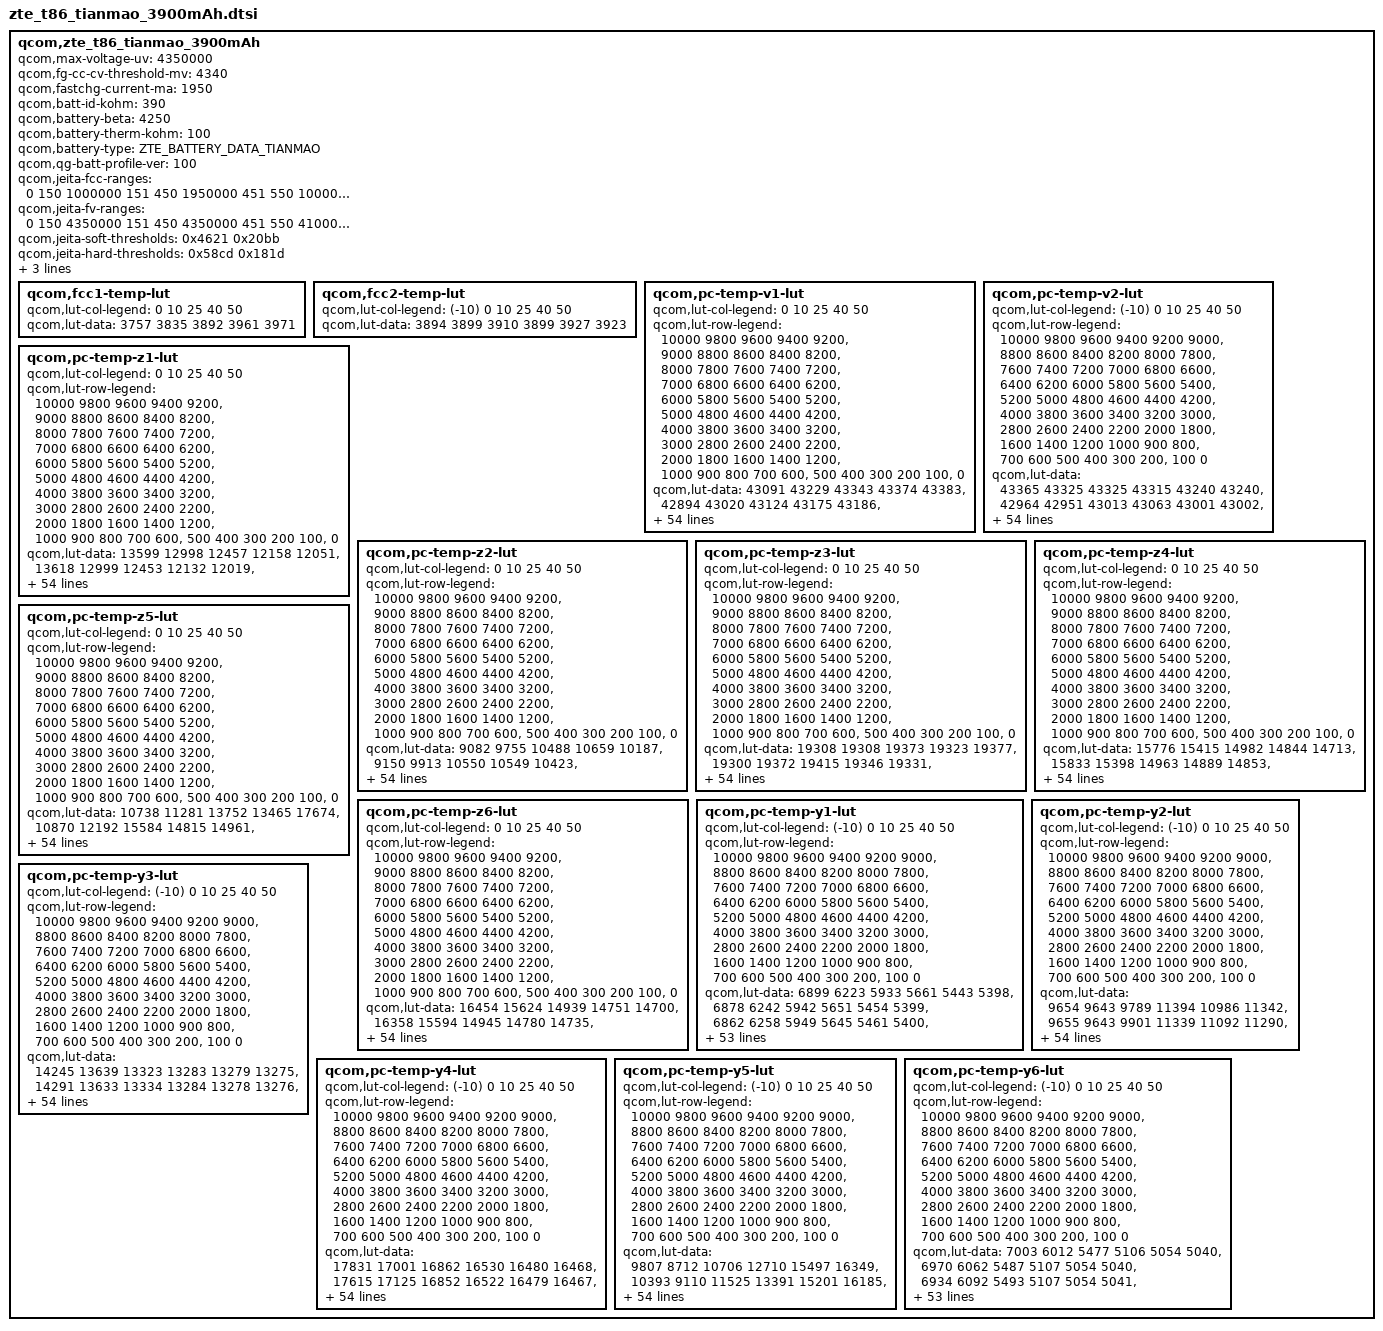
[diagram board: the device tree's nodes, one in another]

qcom,zte_t86_tianmao_3900mAh {
	/* 4215010_ZTE_T86_3900mAH_PMI632_averaged_MasterSlave_Sep26th2019 */
	qcom,max-voltage-uv = <4350000>;
	qcom,fg-cc-cv-threshold-mv = <4340>;
	qcom,fastchg-current-ma = <1950>;
	qcom,batt-id-kohm = <390>;
	qcom,battery-beta = <4250>;
	qcom,battery-therm-kohm = <100>;
	qcom,battery-type = "ZTE_BATTERY_DATA_TIANMAO";
	qcom,qg-batt-profile-ver = <100>;

	qcom,jeita-fcc-ranges = <0   150   1000000
				 151 450  1950000
				 451 550  1000000>;
	qcom,jeita-fv-ranges =  <0   150  4350000
				 151 450  4350000
				 451 550  4100000>;

	/* COOL = 15 DegC, WARM = 45 DegC */
	qcom,jeita-soft-thresholds = <0x4621 0x20bb>;
	/* COLD = 0 DegC, HOT = 55 DegC */
	qcom,jeita-hard-thresholds = <0x58cd 0x181d>;
	/* COOL hys = 17 DegC, WARM hys = 43 DegC */
	qcom,jeita-soft-hys-thresholds = <0x4365 0x22b8>;
	qcom,jeita-soft-fcc-ua = <1000000 1000000>;
	qcom,jeita-soft-fv-uv = <4350000 4100000>;

	qcom,fcc1-temp-lut {
		qcom,lut-col-legend = <0 10 25 40 50>;
		qcom,lut-data = <3757 3835 3892 3961 3971>;
	};

	qcom,fcc2-temp-lut {
		qcom,lut-col-legend = <(-10) 0 10 25 40 50>;
		qcom,lut-data = <3894 3899 3910 3899 3927 3923>;
	};

	qcom,pc-temp-v1-lut {
		qcom,lut-col-legend = <0 10 25 40 50>;
		qcom,lut-row-legend = <10000 9800 9600 9400 9200>,
			<9000 8800 8600 8400 8200>,
			<8000 7800 7600 7400 7200>,
			<7000 6800 6600 6400 6200>,
			<6000 5800 5600 5400 5200>,
			<5000 4800 4600 4400 4200>,
			<4000 3800 3600 3400 3200>,
			<3000 2800 2600 2400 2200>,
			<2000 1800 1600 1400 1200>,
			<1000 900 800 700 600>,
			<500 400 300 200 100>,
			<0>;
		qcom,lut-data = <43091 43229 43343 43374 43383>,
			<42894 43020 43124 43175 43186>,
			<42683 42806 42905 42956 42973>,
			<42470 42583 42687 42730 42750>,
			<42268 42363 42468 42510 42532>,
			<42072 42156 42253 42293 42314>,
			<41882 41957 42043 42076 42097>,
			<41693 41762 41836 41860 41882>,
			<41508 41568 41631 41647 41670>,
			<41337 41380 41426 41435 41458>,
			<41183 41216 41235 41227 41249>,
			<41007 41073 41078 41036 41045>,
			<40743 40895 40923 40870 40848>,
			<40423 40601 40707 40695 40656>,
			<40175 40282 40409 40472 40468>,
			<39993 40078 40162 40231 40283>,
			<39840 39935 40017 40049 40110>,
			<39711 39804 39895 39919 39952>,
			<39602 39681 39739 39781 39789>,
			<39488 39558 39550 39592 39599>,
			<39362 39384 39360 39381 39396>,
			<39225 39128 39167 39188 39204>,
			<39068 38920 38984 39004 39015>,
			<38874 38818 38846 38848 38853>,
			<38717 38744 38739 38728 38727>,
			<38628 38671 38642 38624 38619>,
			<38563 38600 38548 38525 38519>,
			<38507 38534 38461 38433 38428>,
			<38460 38471 38380 38349 38342>,
			<38418 38412 38306 38274 38262>,
			<38379 38359 38239 38206 38189>,
			<38343 38311 38180 38144 38123>,
			<38307 38268 38128 38088 38066>,
			<38274 38228 38080 38035 38007>,
			<38241 38193 38038 37986 37949>,
			<38206 38154 37995 37937 37889>,
			<38169 38117 37951 37884 37824>,
			<38124 38073 37904 37827 37757>,
			<38052 38002 37837 37755 37679>,
			<37954 37896 37742 37660 37587>,
			<37851 37778 37634 37550 37482>,
			<37738 37648 37515 37428 37356>,
			<37607 37508 37382 37292 37214>,
			<37448 37352 37228 37145 37068>,
			<37316 37242 37111 37029 36961>,
			<37233 37168 37045 36965 36903>,
			<37206 37145 37034 36948 36885>,
			<37181 37124 37016 36933 36869>,
			<37153 37098 36995 36909 36842>,
			<37070 37012 36903 36782 36689>,
			<36775 36691 36583 36444 36343>,
			<36325 36238 36136 35987 35885>,
			<35752 35656 35559 35401 35297>,
			<34982 34867 34775 34602 34492>,
			<33775 33630 33562 33353 33231>,
			<30000 30000 30000 30000 30000>;
	};

	qcom,pc-temp-v2-lut {
		qcom,lut-col-legend = <(-10) 0 10 25 40 50>;
		qcom,lut-row-legend = <10000 9800 9600 9400 9200 9000>,
			<8800 8600 8400 8200 8000 7800>,
			<7600 7400 7200 7000 6800 6600>,
			<6400 6200 6000 5800 5600 5400>,
			<5200 5000 4800 4600 4400 4200>,
			<4000 3800 3600 3400 3200 3000>,
			<2800 2600 2400 2200 2000 1800>,
			<1600 1400 1200 1000 900 800>,
			<700 600 500 400 300 200>,
			<100 0>;
		qcom,lut-data = <43365 43325 43325 43315 43240 43240>,
			<42964 42951 43013 43063 43001 43002>,
			<42606 42622 42728 42821 42769 42770>,
			<42298 42349 42474 42590 42542 42543>,
			<42027 42124 42250 42370 42321 42323>,
			<41791 41902 42034 42154 42103 42105>,
			<41575 41642 41818 41940 41887 41888>,
			<41388 41391 41605 41728 41673 41674>,
			<41266 41228 41394 41516 41461 41463>,
			<41193 41127 41179 41302 41251 41254>,
			<41086 41003 40989 41099 41045 41050>,
			<40706 40726 40847 40924 40852 40849>,
			<40157 40366 40712 40752 40660 40653>,
			<39831 40102 40495 40540 40454 40463>,
			<39633 39872 40157 40273 40231 40279>,
			<39451 39665 39869 40042 40039 40101>,
			<39251 39483 39698 39895 39897 39936>,
			<39059 39308 39552 39768 39763 39772>,
			<38890 39119 39375 39598 39587 39585>,
			<38737 38911 39169 39375 39372 39377>,
			<38608 38722 38977 39162 39165 39176>,
			<38508 38562 38815 38979 38971 38982>,
			<38423 38424 38669 38815 38796 38805>,
			<38347 38323 38539 38678 38659 38666>,
			<38280 38245 38422 38562 38545 38552>,
			<38219 38180 38316 38458 38442 38447>,
			<38162 38125 38219 38363 38344 38349>,
			<38107 38077 38132 38274 38253 38257>,
			<38054 38032 38058 38192 38172 38171>,
			<38003 37990 37993 38114 38097 38091>,
			<37954 37949 37937 38043 38028 38018>,
			<37907 37911 37890 37975 37964 37957>,
			<37860 37873 37848 37911 37900 37894>,
			<37812 37831 37807 37846 37825 37811>,
			<37763 37787 37770 37781 37740 37707>,
			<37710 37739 37728 37712 37650 37605>,
			<37650 37687 37674 37635 37556 37503>,
			<37583 37630 37612 37554 37462 37405>,
			<37509 37560 37540 37476 37382 37321>,
			<37427 37471 37457 37402 37309 37245>,
			<37336 37374 37363 37321 37223 37159>,
			<37230 37266 37249 37219 37116 37052>,
			<37116 37151 37130 37103 36995 36932>,
			<37012 37034 37014 36956 36857 36797>,
			<36921 36919 36917 36893 36815 36757>,
			<36846 36820 36850 36869 36792 36734>,
			<36799 36775 36816 36852 36775 36719>,
			<36737 36719 36778 36826 36748 36692>,
			<36643 36652 36703 36774 36671 36599>,
			<36473 36526 36545 36610 36410 36321>,
			<36152 36269 36202 36216 35981 35880>,
			<35663 35829 35684 35710 35431 35324>,
			<34991 35212 35009 35035 34700 34586>,
			<34006 34342 34037 34109 33653 33544>,
			<32357 32897 32653 32689 32370 32090>,
			<27549 29068 27227 28870 27133 26846>;
	};

	qcom,pc-temp-z1-lut {
		qcom,lut-col-legend = <0 10 25 40 50>;
		qcom,lut-row-legend = <10000 9800 9600 9400 9200>,
			<9000 8800 8600 8400 8200>,
			<8000 7800 7600 7400 7200>,
			<7000 6800 6600 6400 6200>,
			<6000 5800 5600 5400 5200>,
			<5000 4800 4600 4400 4200>,
			<4000 3800 3600 3400 3200>,
			<3000 2800 2600 2400 2200>,
			<2000 1800 1600 1400 1200>,
			<1000 900 800 700 600>,
			<500 400 300 200 100>,
			<0>;
		qcom,lut-data = <13599 12998 12457 12158 12051>,
			<13618 12999 12453 12132 12019>,
			<13581 12990 12448 12123 12011>,
			<13554 12978 12436 12116 12010>,
			<13568 12967 12429 12108 12008>,
			<13589 12954 12422 12101 12007>,
			<13598 12938 12410 12096 12006>,
			<13562 12930 12395 12092 12007>,
			<13509 12919 12390 12091 12008>,
			<13491 12905 12389 12094 12010>,
			<13489 12893 12390 12099 12013>,
			<13484 12876 12389 12101 12015>,
			<13448 12858 12386 12098 12017>,
			<13384 12837 12378 12094 12018>,
			<13341 12815 12355 12092 12020>,
			<13305 12798 12343 12089 12022>,
			<13281 12783 12344 12089 12025>,
			<13290 12776 12346 12094 12027>,
			<13321 12787 12350 12099 12030>,
			<13336 12805 12359 12101 12031>,
			<13319 12811 12365 12103 12033>,
			<13296 12814 12367 12104 12034>,
			<13297 12815 12368 12107 12036>,
			<13319 12811 12369 12110 12039>,
			<13335 12804 12370 12113 12043>,
			<13330 12803 12371 12115 12048>,
			<13320 12811 12375 12119 12053>,
			<13310 12819 12380 12126 12057>,
			<13300 12819 12384 12132 12062>,
			<13293 12814 12389 12135 12066>,
			<13293 12814 12393 12137 12069>,
			<13297 12817 12397 12142 12074>,
			<13303 12820 12404 12149 12078>,
			<13320 12828 12409 12154 12083>,
			<13343 12839 12415 12159 12087>,
			<13357 12847 12420 12163 12091>,
			<13371 12854 12427 12169 12096>,
			<13379 12859 12432 12175 12101>,
			<13383 12859 12434 12180 12105>,
			<13386 12858 12436 12184 12109>,
			<13388 12857 12439 12187 12113>,
			<13394 12868 12445 12192 12117>,
			<13409 12883 12454 12196 12121>,
			<13464 12903 12473 12199 12124>,
			<13462 12919 12476 12204 12126>,
			<13488 12910 12478 12210 12129>,
			<13498 12899 12488 12211 12131>,
			<13489 12910 12489 12210 12133>,
			<13507 12920 12492 12219 12137>,
			<13518 12959 12495 12228 12144>,
			<13530 12954 12511 12231 12151>,
			<13545 12975 12523 12243 12161>,
			<13566 13001 12537 12254 12173>,
			<13615 13041 12549 12269 12186>,
			<13615 13041 12549 12269 12186>,
			<13615 13041 12549 12269 12186>;
	};

	qcom,pc-temp-z2-lut {
		qcom,lut-col-legend = <0 10 25 40 50>;
		qcom,lut-row-legend = <10000 9800 9600 9400 9200>,
			<9000 8800 8600 8400 8200>,
			<8000 7800 7600 7400 7200>,
			<7000 6800 6600 6400 6200>,
			<6000 5800 5600 5400 5200>,
			<5000 4800 4600 4400 4200>,
			<4000 3800 3600 3400 3200>,
			<3000 2800 2600 2400 2200>,
			<2000 1800 1600 1400 1200>,
			<1000 900 800 700 600>,
			<500 400 300 200 100>,
			<0>;
		qcom,lut-data = <9082 9755 10488 10659 10187>,
			<9150 9913 10550 10549 10423>,
			<9514 9989 10588 10584 10506>,
			<9883 10134 10590 10612 10593>,
			<9926 10278 10579 10603 10602>,
			<9870 10281 10566 10571 10589>,
			<9785 10260 10542 10549 10571>,
			<9655 10244 10513 10541 10492>,
			<9533 10232 10496 10539 10410>,
			<9539 10224 10481 10542 10418>,
			<9664 10235 10474 10547 10462>,
			<9772 10273 10490 10536 10478>,
			<9831 10292 10514 10476 10454>,
			<9907 10262 10526 10429 10428>,
			<9936 10222 10535 10474 10423>,
			<9945 10219 10539 10563 10428>,
			<9958 10236 10536 10577 10440>,
			<9979 10250 10532 10527 10468>,
			<10010 10258 10539 10491 10509>,
			<10025 10264 10565 10559 10570>,
			<10021 10262 10584 10676 10656>,
			<10014 10242 10588 10716 10752>,
			<10017 10227 10589 10728 10878>,
			<10032 10236 10591 10729 10947>,
			<10046 10254 10597 10717 10859>,
			<10053 10261 10601 10694 10695>,
			<10059 10263 10558 10653 10589>,
			<10061 10264 10493 10572 10506>,
			<10062 10260 10482 10526 10466>,
			<10064 10253 10484 10516 10460>,
			<10069 10252 10487 10513 10459>,
			<10079 10257 10501 10523 10459>,
			<10086 10264 10527 10555 10463>,
			<10090 10273 10552 10593 10477>,
			<10095 10285 10582 10642 10546>,
			<10102 10295 10611 10692 10637>,
			<10111 10301 10634 10729 10702>,
			<10118 10308 10655 10764 10759>,
			<10122 10320 10677 10784 10793>,
			<10122 10339 10702 10800 10811>,
			<10063 10350 10718 10812 10824>,
			<9639 10352 10724 10817 10826>,
			<9440 10358 10727 10820 10815>,
			<9425 10403 10734 10776 10786>,
			<9404 10219 10816 10772 10727>,
			<9473 10122 10877 10760 10688>,
			<9447 10099 10959 10716 10686>,
			<9432 10023 10945 10732 10686>,
			<9442 10025 11090 10830 10837>,
			<9435 9883 11309 10840 10668>,
			<9358 9873 11432 10672 10518>,
			<9320 9724 11416 10627 10456>,
			<9297 9678 11252 10549 10420>,
			<9238 9642 11230 10528 10352>,
			<9238 9642 11230 10528 10352>,
			<9238 9642 11230 10528 10352>;
	};

	qcom,pc-temp-z3-lut {
		qcom,lut-col-legend = <0 10 25 40 50>;
		qcom,lut-row-legend = <10000 9800 9600 9400 9200>,
			<9000 8800 8600 8400 8200>,
			<8000 7800 7600 7400 7200>,
			<7000 6800 6600 6400 6200>,
			<6000 5800 5600 5400 5200>,
			<5000 4800 4600 4400 4200>,
			<4000 3800 3600 3400 3200>,
			<3000 2800 2600 2400 2200>,
			<2000 1800 1600 1400 1200>,
			<1000 900 800 700 600>,
			<500 400 300 200 100>,
			<0>;
		qcom,lut-data = <19308 19308 19373 19323 19377>,
			<19300 19372 19415 19346 19331>,
			<19357 19413 19445 19366 19345>,
			<19432 19501 19456 19389 19367>,
			<19471 19584 19462 19394 19375>,
			<19500 19600 19465 19396 19380>,
			<19510 19606 19463 19398 19381>,
			<19421 19608 19460 19401 19379>,
			<19294 19608 19461 19404 19377>,
			<19288 19608 19465 19403 19376>,
			<19407 19592 19468 19400 19375>,
			<19510 19540 19458 19394 19373>,
			<19613 19514 19443 19379 19366>,
			<19780 19558 19442 19368 19359>,
			<19833 19616 19449 19374 19358>,
			<19810 19619 19453 19386 19358>,
			<19775 19595 19445 19387 19356>,
			<19737 19578 19435 19373 19352>,
			<19693 19575 19435 19364 19348>,
			<19675 19576 19445 19369 19350>,
			<19702 19581 19452 19377 19353>,
			<19745 19596 19443 19377 19358>,
			<19770 19606 19431 19369 19365>,
			<19793 19599 19432 19364 19374>,
			<19806 19585 19443 19377 19387>,
			<19801 19580 19454 19398 19401>,
			<19789 19578 19462 19407 19402>,
			<19777 19578 19468 19411 19395>,
			<19762 19580 19468 19413 19388>,
			<19745 19583 19465 19408 19384>,
			<19725 19584 19461 19401 19379>,
			<19700 19581 19455 19396 19374>,
			<19683 19577 19448 19391 19367>,
			<19673 19574 19444 19386 19361>,
			<19664 19570 19441 19380 19357>,
			<19652 19566 19438 19374 19353>,
			<19637 19558 19435 19374 19354>,
			<19626 19550 19433 19373 19356>,
			<19624 19548 19431 19373 19357>,
			<19621 19547 19427 19374 19356>,
			<19579 19546 19424 19375 19356>,
			<19364 19542 19419 19374 19358>,
			<19275 19536 19415 19372 19362>,
			<19275 19521 19414 19370 19364>,
			<19275 19404 19398 19364 19358>,
			<19271 19338 19387 19346 19335>,
			<19273 19327 19338 19340 19328>,
			<19273 19316 19344 19338 19328>,
			<19272 19309 19329 19329 19318>,
			<19274 19267 19315 19338 19339>,
			<19285 19285 19305 19352 19350>,
			<19280 19273 19305 19360 19350>,
			<19282 19274 19308 19359 19351>,
			<19290 19274 19313 19356 19355>,
			<19290 19274 19313 19356 19355>,
			<19290 19274 19313 19356 19355>;
	};

	qcom,pc-temp-z4-lut {
		qcom,lut-col-legend = <0 10 25 40 50>;
		qcom,lut-row-legend = <10000 9800 9600 9400 9200>,
			<9000 8800 8600 8400 8200>,
			<8000 7800 7600 7400 7200>,
			<7000 6800 6600 6400 6200>,
			<6000 5800 5600 5400 5200>,
			<5000 4800 4600 4400 4200>,
			<4000 3800 3600 3400 3200>,
			<3000 2800 2600 2400 2200>,
			<2000 1800 1600 1400 1200>,
			<1000 900 800 700 600>,
			<500 400 300 200 100>,
			<0>;
		qcom,lut-data = <15776 15415 14982 14844 14713>,
			<15833 15398 14963 14889 14853>,
			<15765 15363 14940 14878 14845>,
			<15668 15249 14910 14860 14829>,
			<15588 15117 14871 14840 14811>,
			<15493 15041 14836 14815 14789>,
			<15437 14982 14812 14791 14770>,
			<15491 14936 14791 14769 14756>,
			<15579 14898 14772 14751 14744>,
			<15553 14870 14753 14737 14730>,
			<15377 14861 14736 14726 14716>,
			<15223 14862 14720 14717 14708>,
			<15117 14858 14707 14708 14704>,
			<14966 14834 14708 14703 14701>,
			<14908 14801 14723 14704 14696>,
			<14897 14784 14731 14706 14688>,
			<14891 14771 14714 14704 14682>,
			<14891 14759 14690 14687 14675>,
			<14897 14745 14689 14676 14671>,
			<14898 14733 14711 14693 14687>,
			<14856 14746 14739 14729 14723>,
			<14802 14828 14785 14764 14748>,
			<14799 14886 14833 14806 14769>,
			<14834 14881 14836 14827 14780>,
			<14859 14866 14807 14804 14761>,
			<14856 14851 14775 14765 14728>,
			<14850 14831 14750 14740 14713>,
			<14845 14811 14727 14722 14706>,
			<14836 14792 14713 14710 14700>,
			<14829 14772 14704 14702 14693>,
			<14829 14759 14698 14697 14688>,
			<14833 14748 14695 14693 14684>,
			<14834 14741 14694 14690 14681>,
			<14831 14736 14693 14689 14680>,
			<14827 14732 14694 14693 14684>,
			<14826 14731 14695 14698 14689>,
			<14829 14731 14696 14699 14694>,
			<14831 14733 14698 14700 14697>,
			<14829 14734 14701 14701 14698>,
			<14830 14736 14705 14702 14697>,
			<14872 14738 14707 14702 14694>,
			<15104 14736 14704 14699 14690>,
			<15199 14734 14701 14695 14686>,
			<15176 14737 14701 14696 14685>,
			<15076 14805 14693 14689 14680>,
			<15047 14845 14672 14673 14667>,
			<15039 14849 14714 14665 14660>,
			<15030 14854 14696 14649 14641>,
			<15023 14854 14707 14650 14640>,
			<15012 14891 14729 14655 14641>,
			<15016 14888 14756 14660 14648>,
			<15031 14904 14758 14656 14653>,
			<15036 14906 14758 14659 14656>,
			<15046 14911 14755 14664 14653>,
			<15046 14911 14755 14664 14653>,
			<15046 14911 14755 14664 14653>;
	};

	qcom,pc-temp-z5-lut {
		qcom,lut-col-legend = <0 10 25 40 50>;
		qcom,lut-row-legend = <10000 9800 9600 9400 9200>,
			<9000 8800 8600 8400 8200>,
			<8000 7800 7600 7400 7200>,
			<7000 6800 6600 6400 6200>,
			<6000 5800 5600 5400 5200>,
			<5000 4800 4600 4400 4200>,
			<4000 3800 3600 3400 3200>,
			<3000 2800 2600 2400 2200>,
			<2000 1800 1600 1400 1200>,
			<1000 900 800 700 600>,
			<500 400 300 200 100>,
			<0>;
		qcom,lut-data = <10738 11281 13752 13465 17674>,
			<10870 12192 15584 14815 14961>,
			<11185 13013 16995 16068 15988>,
			<11560 14368 17852 17575 17612>,
			<11845 15784 18498 17990 18417>,
			<12104 16627 18873 18182 18938>,
			<12199 17261 19046 18486 19228>,
			<11699 17886 19280 19347 19319>,
			<10994 18711 20036 20331 19417>,
			<10933 19335 21880 21087 19957>,
			<11550 18721 22974 21759 21138>,
			<12449 16417 22790 21775 21786>,
			<15224 15310 22464 20297 21466>,
			<19695 21600 23142 19074 21173>,
			<21073 29861 26038 21581 21911>,
			<20176 30239 27742 26417 23297>,
			<18882 26369 27239 27346 24215>,
			<17655 24015 26513 25553 24809>,
			<16281 25653 27926 24281 25309>,
			<15746 28614 35032 25936 25695>,
			<18548 31239 39326 28630 25770>,
			<23717 36111 32571 27880 24917>,
			<29574 39239 22656 21522 21517>,
			<38886 35269 20706 17699 19272>,
			<44565 27763 20639 18260 20592>,
			<42211 24701 20793 19475 22881>,
			<36824 23574 22369 21201 23753>,
			<32534 23046 25173 24001 24062>,
			<29116 23671 27677 26235 24492>,
			<26090 25330 30267 27635 25828>,
			<23463 26868 32269 28910 27498>,
			<21091 28350 33577 30796 28491>,
			<19782 29728 34600 33597 29255>,
			<19203 30976 35300 34622 29613>,
			<18742 32167 35872 33667 29628>,
			<18232 32456 36115 32391 29566>,
			<17665 30785 35300 31668 29622>,
			<17374 28821 33600 31017 29709>,
			<17635 28416 31856 30277 29360>,
			<17915 28637 29783 29177 27586>,
			<16963 28567 27891 27957 26056>,
			<12702 27837 26056 26901 26898>,
			<10991 26607 24781 25811 28421>,
			<11041 24013 24400 24126 27945>,
			<11229 16118 23202 23212 25365>,
			<11228 12854 23684 21189 20104>,
			<11183 12497 15294 20361 19679>,
			<11194 12213 16046 22556 23182>,
			<11204 12117 14862 20767 21863>,
			<11285 11593 13808 20791 26719>,
			<11353 11765 13020 20879 24762>,
			<11247 11551 12948 22507 22822>,
			<11220 11499 12956 20903 21426>,
			<11147 11451 13075 19361 21107>,
			<11147 11451 13075 19361 21107>,
			<11147 11451 13075 19361 21107>;
	};

	qcom,pc-temp-z6-lut {
		qcom,lut-col-legend = <0 10 25 40 50>;
		qcom,lut-row-legend = <10000 9800 9600 9400 9200>,
			<9000 8800 8600 8400 8200>,
			<8000 7800 7600 7400 7200>,
			<7000 6800 6600 6400 6200>,
			<6000 5800 5600 5400 5200>,
			<5000 4800 4600 4400 4200>,
			<4000 3800 3600 3400 3200>,
			<3000 2800 2600 2400 2200>,
			<2000 1800 1600 1400 1200>,
			<1000 900 800 700 600>,
			<500 400 300 200 100>,
			<0>;
		qcom,lut-data = <16454 15624 14939 14751 14700>,
			<16358 15594 14945 14780 14735>,
			<16260 15557 14943 14783 14739>,
			<16165 15508 14933 14785 14741>,
			<16075 15454 14915 14780 14737>,
			<15989 15403 14896 14768 14730>,
			<15912 15352 14881 14758 14722>,
			<15846 15309 14867 14750 14716>,
			<15786 15276 14856 14743 14710>,
			<15728 15245 14849 14737 14704>,
			<15672 15207 14840 14731 14698>,
			<15625 15164 14824 14724 14692>,
			<15593 15136 14809 14711 14687>,
			<15566 15125 14808 14702 14683>,
			<15536 15116 14811 14705 14679>,
			<15498 15102 14813 14712 14676>,
			<15463 15081 14803 14711 14673>,
			<15434 15068 14790 14698 14668>,
			<15409 15065 14790 14688 14664>,
			<15396 15063 14805 14698 14672>,
			<15392 15071 14822 14718 14689>,
			<15389 15114 14839 14734 14704>,
			<15395 15145 14854 14750 14720>,
			<15424 15141 14855 14757 14728>,
			<15445 15130 14850 14754 14726>,
			<15443 15121 14845 14749 14722>,
			<15436 15113 14839 14745 14717>,
			<15429 15106 14834 14741 14712>,
			<15419 15101 14829 14737 14706>,
			<15409 15097 14824 14731 14702>,
			<15400 15094 14821 14727 14697>,
			<15392 15090 14817 14723 14693>,
			<15387 15088 14815 14720 14688>,
			<15384 15088 14815 14718 14686>,
			<15383 15088 14815 14717 14686>,
			<15382 15089 14816 14717 14686>,
			<15383 15089 14817 14717 14688>,
			<15383 15091 14818 14718 14691>,
			<15388 15094 14820 14719 14692>,
			<15399 15102 14822 14721 14692>,
			<15406 15108 14823 14723 14691>,
			<15411 15113 14822 14722 14691>,
			<15416 15117 14820 14720 14692>,
			<15424 15120 14822 14720 14693>,
			<15404 15106 14815 14715 14689>,
			<15395 15095 14803 14700 14672>,
			<15394 15093 14796 14693 14666>,
			<15393 15093 14793 14687 14658>,
			<15396 15094 14793 14683 14652>,
			<15400 15100 14799 14691 14665>,
			<15414 15113 14809 14703 14677>,
			<15429 15122 14813 14707 14681>,
			<15446 15133 14818 14711 14684>,
			<15473 15150 14825 14716 14689>,
			<15473 15150 14825 14716 14689>,
			<15473 15150 14825 14716 14689>;
	};

	qcom,pc-temp-y1-lut {
		qcom,lut-col-legend = <(-10) 0 10 25 40 50>;
		qcom,lut-row-legend = <10000 9800 9600 9400 9200 9000>,
			<8800 8600 8400 8200 8000 7800>,
			<7600 7400 7200 7000 6800 6600>,
			<6400 6200 6000 5800 5600 5400>,
			<5200 5000 4800 4600 4400 4200>,
			<4000 3800 3600 3400 3200 3000>,
			<2800 2600 2400 2200 2000 1800>,
			<1600 1400 1200 1000 900 800>,
			<700 600 500 400 300 200>,
			<100 0>;
		qcom,lut-data = <6899 6223 5933 5661 5443 5398>,
			<6878 6242 5942 5651 5454 5399>,
			<6862 6258 5949 5645 5461 5400>,
			<6849 6271 5954 5642 5464 5401>,
			<6840 6280 5957 5641 5464 5402>,
			<6835 6284 5958 5641 5464 5402>,
			<6837 6282 5955 5649 5459 5402>,
			<6841 6277 5952 5662 5453 5402>,
			<6838 6277 5950 5662 5452 5401>,
			<6825 6282 5947 5652 5453 5399>,
			<6817 6285 5945 5644 5453 5397>,
			<6826 6289 5942 5641 5452 5395>,
			<6841 6295 5939 5638 5450 5393>,
			<6847 6296 5942 5636 5450 5394>,
			<6851 6293 5951 5632 5451 5397>,
			<6854 6291 5956 5630 5451 5399>,
			<6862 6293 5952 5633 5450 5396>,
			<6870 6295 5947 5638 5447 5392>,
			<6868 6296 5947 5638 5447 5393>,
			<6847 6297 5950 5636 5446 5398>,
			<6832 6298 5952 5634 5446 5402>,
			<6839 6296 5953 5634 5448 5401>,
			<6851 6293 5953 5633 5450 5400>,
			<6863 6292 5952 5634 5451 5401>,
			<6878 6293 5949 5635 5454 5402>,
			<6887 6294 5947 5636 5455 5405>,
			<6870 6291 5948 5637 5456 5409>,
			<6842 6289 5948 5638 5456 5412>,
			<6834 6289 5949 5639 5458 5415>,
			<6832 6291 5950 5641 5462 5416>,
			<6831 6293 5952 5644 5465 5418>,
			<6825 6296 5958 5650 5468 5423>,
			<6815 6301 5964 5656 5471 5427>,
			<6818 6300 5967 5657 5474 5428>,
			<6841 6294 5968 5653 5478 5428>,
			<6857 6290 5968 5651 5480 5430>,
			<6848 6291 5967 5654 5480 5433>,
			<6832 6293 5965 5659 5480 5435>,
			<6830 6296 5965 5662 5484 5436>,
			<6838 6299 5966 5664 5491 5436>,
			<6847 6301 5969 5666 5493 5436>,
			<6853 6307 5979 5670 5493 5441>,
			<6857 6314 5985 5674 5494 5445>,
			<6848 6310 5969 5678 5500 5445>,
			<6839 6312 5977 5681 5504 5450>,
			<6892 6315 5995 5691 5505 5457>,
			<6901 6344 5990 5688 5505 5453>,
			<6876 6327 5984 5689 5508 5455>,
			<6876 6336 5989 5688 5508 5457>,
			<6919 6341 6000 5692 5508 5457>,
			<6917 6344 5983 5688 5514 5463>,
			<6918 6332 6004 5706 5519 5468>,
			<6943 6381 6009 5713 5525 5476>,
			<6963 6389 6028 5728 5538 5485>,
			<6963 6389 6028 5728 5538 5485>,
			<6963 6389 6028 5728 5538 5485>;
	};

	qcom,pc-temp-y2-lut {
		qcom,lut-col-legend = <(-10) 0 10 25 40 50>;
		qcom,lut-row-legend = <10000 9800 9600 9400 9200 9000>,
			<8800 8600 8400 8200 8000 7800>,
			<7600 7400 7200 7000 6800 6600>,
			<6400 6200 6000 5800 5600 5400>,
			<5200 5000 4800 4600 4400 4200>,
			<4000 3800 3600 3400 3200 3000>,
			<2800 2600 2400 2200 2000 1800>,
			<1600 1400 1200 1000 900 800>,
			<700 600 500 400 300 200>,
			<100 0>;
		qcom,lut-data = <9654 9643 9789 11394 10986 11342>,
			<9655 9643 9901 11339 11092 11290>,
			<9656 9647 10109 11296 11169 11239>,
			<9657 9705 10344 11262 11219 11190>,
			<9657 9775 10540 11236 11246 11146>,
			<9658 9856 10628 11216 11254 11108>,
			<9658 10043 10639 11208 11229 11069>,
			<9657 10275 10645 11205 11185 11039>,
			<9657 10321 10634 11192 11155 11040>,
			<9658 10169 10583 11166 11131 11066>,
			<9658 10063 10552 11134 11107 11081>,
			<9658 10068 10637 11087 11070 11053>,
			<9657 10070 10767 11042 11035 11012>,
			<9657 10031 10804 11038 11047 11002>,
			<9657 9828 10812 11066 11113 11011>,
			<9657 9696 10819 11099 11149 11019>,
			<9657 9696 10840 11129 11139 11044>,
			<9657 9697 10862 11161 11126 11074>,
			<9657 9694 10864 11189 11145 11097>,
			<9657 9684 10857 11215 11217 11159>,
			<9657 9676 10853 11242 11257 11189>,
			<9657 9675 10875 11270 11250 11208>,
			<9657 9675 10907 11304 11240 11233>,
			<9657 9674 10900 11359 11267 11243>,
			<9657 9673 10829 11456 11343 11273>,
			<9657 9673 10788 11515 11382 11300>,
			<9657 9671 10779 11513 11379 11319>,
			<9657 9670 10767 11499 11376 11336>,
			<9656 9668 10778 11495 11417 11372>,
			<9656 9667 10823 11493 11532 11438>,
			<9656 9666 10826 11493 11606 11488>,
			<9656 9665 10666 11492 11643 11532>,
			<9656 9664 10462 11491 11665 11565>,
			<9656 9663 10415 11486 11648 11548>,
			<9656 9662 10462 11472 11585 11489>,
			<9656 9661 10471 11461 11519 11460>,
			<9656 9660 10313 11494 11436 11453>,
			<9656 9659 10105 11548 11377 11448>,
			<9656 9658 10009 11561 11415 11439>,
			<9655 9657 9949 11572 11521 11415>,
			<9655 9657 9894 11569 11567 11407>,
			<9655 9656 9837 11483 11538 11440>,
			<9655 9656 9788 11406 11522 11450>,
			<9655 9655 9744 11469 11504 11357>,
			<9655 9655 9719 11414 11483 11307>,
			<9654 9655 9716 11374 11374 11183>,
			<9654 9654 9707 11368 11283 11178>,
			<9654 9654 9705 11289 11299 11172>,
			<9654 9654 9709 11227 11290 11156>,
			<9654 9654 9706 11236 11193 11089>,
			<9653 9654 9691 11228 11153 11047>,
			<9653 9654 9682 11138 11131 11029>,
			<9653 9653 9673 11067 11036 10912>,
			<9653 9653 9670 10943 10840 10712>,
			<9653 9653 9670 10943 10840 10712>,
			<9653 9653 9670 10943 10840 10712>;
	};

	qcom,pc-temp-y3-lut {
		qcom,lut-col-legend = <(-10) 0 10 25 40 50>;
		qcom,lut-row-legend = <10000 9800 9600 9400 9200 9000>,
			<8800 8600 8400 8200 8000 7800>,
			<7600 7400 7200 7000 6800 6600>,
			<6400 6200 6000 5800 5600 5400>,
			<5200 5000 4800 4600 4400 4200>,
			<4000 3800 3600 3400 3200 3000>,
			<2800 2600 2400 2200 2000 1800>,
			<1600 1400 1200 1000 900 800>,
			<700 600 500 400 300 200>,
			<100 0>;
		qcom,lut-data = <14245 13639 13323 13283 13279 13275>,
			<14291 13633 13334 13284 13278 13276>,
			<14295 13627 13349 13287 13278 13276>,
			<14267 13620 13365 13290 13278 13276>,
			<14217 13613 13378 13293 13278 13276>,
			<14152 13605 13385 13294 13279 13276>,
			<14036 13599 13387 13294 13280 13276>,
			<13913 13592 13389 13294 13281 13276>,
			<13900 13573 13392 13293 13281 13277>,
			<13952 13522 13399 13293 13279 13278>,
			<13987 13488 13402 13293 13278 13279>,
			<13954 13494 13404 13298 13281 13279>,
			<13898 13508 13405 13307 13284 13278>,
			<13874 13509 13400 13308 13286 13279>,
			<13861 13502 13384 13304 13287 13281>,
			<13855 13498 13372 13301 13288 13283>,
			<13855 13495 13368 13306 13291 13284>,
			<13856 13488 13366 13315 13293 13284>,
			<13855 13477 13361 13315 13293 13284>,
			<13851 13446 13353 13307 13291 13284>,
			<13847 13421 13346 13300 13288 13284>,
			<13856 13405 13341 13295 13283 13280>,
			<13873 13390 13336 13292 13278 13276>,
			<13890 13388 13329 13289 13277 13275>,
			<13912 13394 13319 13287 13278 13275>,
			<13935 13403 13312 13285 13278 13275>,
			<13959 13422 13307 13287 13277 13276>,
			<13984 13448 13303 13289 13277 13276>,
			<14011 13467 13303 13290 13278 13276>,
			<14039 13481 13302 13288 13281 13274>,
			<14070 13497 13301 13287 13282 13273>,
			<14107 13520 13301 13288 13281 13275>,
			<14148 13549 13300 13290 13280 13277>,
			<14191 13579 13302 13290 13280 13276>,
			<14236 13609 13310 13291 13280 13274>,
			<14282 13644 13316 13291 13280 13273>,
			<14327 13687 13316 13286 13279 13274>,
			<14373 13736 13317 13280 13277 13275>,
			<14426 13788 13321 13277 13277 13276>,
			<14488 13844 13327 13276 13276 13277>,
			<14554 13906 13334 13276 13276 13277>,
			<14621 13977 13344 13281 13276 13278>,
			<14691 14058 13358 13287 13276 13278>,
			<14769 14149 13377 13282 13275 13275>,
			<14866 14254 13393 13286 13278 13277>,
			<14891 14249 13402 13291 13283 13281>,
			<14934 14310 13419 13294 13286 13284>,
			<14999 14357 13447 13297 13290 13286>,
			<15074 14420 13471 13303 13291 13286>,
			<15137 14472 13488 13306 13285 13282>,
			<15197 14510 13495 13297 13288 13282>,
			<15297 14596 13518 13304 13291 13286>,
			<15447 14747 13577 13306 13293 13289>,
			<15612 14917 13669 13315 13297 13292>,
			<15612 14917 13669 13315 13297 13292>,
			<15612 14917 13669 13315 13297 13292>;
	};

	qcom,pc-temp-y4-lut {
		qcom,lut-col-legend = <(-10) 0 10 25 40 50>;
		qcom,lut-row-legend = <10000 9800 9600 9400 9200 9000>,
			<8800 8600 8400 8200 8000 7800>,
			<7600 7400 7200 7000 6800 6600>,
			<6400 6200 6000 5800 5600 5400>,
			<5200 5000 4800 4600 4400 4200>,
			<4000 3800 3600 3400 3200 3000>,
			<2800 2600 2400 2200 2000 1800>,
			<1600 1400 1200 1000 900 800>,
			<700 600 500 400 300 200>,
			<100 0>;
		qcom,lut-data = <17831 17001 16862 16530 16480 16468>,
			<17615 17125 16852 16522 16479 16467>,
			<17521 17218 16845 16515 16479 16467>,
			<17519 17282 16842 16510 16479 16467>,
			<17581 17320 16842 16508 16480 16468>,
			<17677 17332 16846 16508 16481 16469>,
			<17887 17302 16857 16511 16482 16471>,
			<18157 17254 16869 16516 16484 16474>,
			<18292 17326 16869 16522 16487 16476>,
			<18381 17753 16860 16530 16495 16477>,
			<18419 18029 16856 16539 16503 16479>,
			<18072 17818 16989 16553 16510 16484>,
			<17502 17472 17183 16566 16516 16490>,
			<17334 17349 17179 16568 16518 16495>,
			<17300 17293 17005 16566 16519 16499>,
			<17264 17256 16901 16564 16520 16505>,
			<17186 17224 16921 16601 16546 16522>,
			<17096 17176 16950 16657 16578 16541>,
			<17046 17110 16933 16660 16579 16544>,
			<17013 17010 16830 16614 16569 16541>,
			<16995 16922 16736 16566 16556 16534>,
			<16991 16852 16678 16531 16521 16507>,
			<16990 16796 16636 16502 16483 16477>,
			<16989 16787 16623 16495 16477 16471>,
			<16982 16786 16618 16497 16474 16469>,
			<16978 16786 16616 16498 16474 16468>,
			<16982 16785 16610 16497 16476 16469>,
			<16988 16785 16602 16496 16480 16472>,
			<16994 16788 16598 16499 16484 16476>,
			<17005 16807 16591 16508 16490 16483>,
			<17014 16828 16589 16515 16497 16491>,
			<17022 16844 16600 16518 16511 16503>,
			<17029 16860 16617 16520 16522 16512>,
			<17036 16877 16627 16519 16519 16508>,
			<17043 16895 16635 16510 16505 16491>,
			<17049 16913 16642 16502 16492 16478>,
			<17056 16933 16657 16497 16478 16471>,
			<17062 16952 16677 16493 16468 16466>,
			<17065 16960 16690 16494 16469 16466>,
			<17067 16965 16702 16502 16475 16468>,
			<17067 16969 16714 16507 16478 16469>,
			<17056 16973 16728 16504 16479 16469>,
			<17045 16977 16745 16500 16476 16466>,
			<17048 17002 16770 16501 16463 16451>,
			<17065 17039 16814 16500 16469 16459>,
			<17066 17014 16819 16507 16488 16487>,
			<17097 17053 16867 16518 16509 16516>,
			<17143 17110 16924 16544 16551 16560>,
			<17198 17187 16988 16580 16559 16550>,
			<17245 17251 17027 16573 16507 16490>,
			<17212 17256 17003 16530 16493 16478>,
			<17200 17221 16989 16548 16503 16487>,
			<17228 17230 17057 16571 16530 16509>,
			<17330 17310 17166 16665 16663 16646>,
			<17330 17310 17166 16665 16663 16646>,
			<17330 17310 17166 16665 16663 16646>;
	};

	qcom,pc-temp-y5-lut {
		qcom,lut-col-legend = <(-10) 0 10 25 40 50>;
		qcom,lut-row-legend = <10000 9800 9600 9400 9200 9000>,
			<8800 8600 8400 8200 8000 7800>,
			<7600 7400 7200 7000 6800 6600>,
			<6400 6200 6000 5800 5600 5400>,
			<5200 5000 4800 4600 4400 4200>,
			<4000 3800 3600 3400 3200 3000>,
			<2800 2600 2400 2200 2000 1800>,
			<1600 1400 1200 1000 900 800>,
			<700 600 500 400 300 200>,
			<100 0>;
		qcom,lut-data = <9807 8712 10706 12710 15497 16349>,
			<10393 9110 11525 13391 15201 16185>,
			<10778 10602 12612 13994 14913 15914>,
			<11002 11775 13722 14463 14651 15593>,
			<11108 12561 14606 14740 14430 15279>,
			<11133 12891 15018 14770 14269 15027>,
			<10981 12602 15063 14528 14293 14761>,
			<10743 12088 15013 14155 14385 14511>,
			<11110 12020 14770 13790 14140 14459>,
			<13344 12199 14037 13355 13349 14550>,
			<14822 12316 13595 13133 12920 14520>,
			<13780 13029 13832 13602 13211 13979>,
			<12091 14133 14194 14328 13659 13344>,
			<11692 14149 14289 14355 13868 13386>,
			<11819 13152 14476 13761 13992 13924>,
			<11928 12626 14734 13376 14077 14212>,
			<11920 13170 15215 13719 14095 13967>,
			<11888 13829 15833 14433 14123 13651>,
			<11751 13850 16278 15147 14636 14039>,
			<11271 13268 16666 16010 16119 15631>,
			<10912 12652 16837 16527 16813 16431>,
			<10839 11990 16734 16394 16177 16130>,
			<10804 11308 16478 16070 15397 15766>,
			<10815 11109 15934 15840 15370 15814>,
			<10906 11016 14664 14986 15705 16118>,
			<10968 10974 13789 14445 15834 16263>,
			<10990 11091 13300 15026 15564 16239>,
			<11027 11283 12877 15906 15282 16184>,
			<11035 11337 12794 16028 15676 15806>,
			<11040 11288 12659 15726 16924 14782>,
			<11060 11257 12513 15526 17432 14365>,
			<11143 11340 12261 15875 17108 15227>,
			<11274 11463 12005 16553 16768 16207>,
			<11376 11505 12125 17149 17074 16171>,
			<11504 11522 12726 17924 17982 15689>,
			<11590 11548 13052 18335 18313 15562>,
			<11581 11664 12666 16707 17919 16467>,
			<11534 11817 12126 14043 17330 17456>,
			<11515 11851 11977 13153 16702 17655>,
			<11510 11822 11923 12829 15935 17745>,
			<11500 11782 11907 12708 15552 17836>,
			<11399 11755 11864 13886 15407 17954>,
			<11267 11724 11854 15073 15407 17961>,
			<11169 11573 11901 13673 15626 17370>,
			<11126 11552 11687 14515 15723 16145>,
			<11193 11627 11678 14978 16146 16194>,
			<11173 11927 11794 15201 16200 16193>,
			<11289 12175 12438 15175 16124 15580>,
			<11473 12762 13018 15684 16265 15483>,
			<11595 13191 13413 16989 16114 16121>,
			<11562 13182 13061 15663 18404 16760>,
			<11417 12672 12479 17475 18878 17851>,
			<11462 12112 12243 16676 18365 18433>,
			<11426 11526 12161 17344 17879 18063>,
			<11426 11526 12161 17344 17879 18063>,
			<11426 11526 12161 17344 17879 18063>;
	};

	qcom,pc-temp-y6-lut {
		qcom,lut-col-legend = <(-10) 0 10 25 40 50>;
		qcom,lut-row-legend = <10000 9800 9600 9400 9200 9000>,
			<8800 8600 8400 8200 8000 7800>,
			<7600 7400 7200 7000 6800 6600>,
			<6400 6200 6000 5800 5600 5400>,
			<5200 5000 4800 4600 4400 4200>,
			<4000 3800 3600 3400 3200 3000>,
			<2800 2600 2400 2200 2000 1800>,
			<1600 1400 1200 1000 900 800>,
			<700 600 500 400 300 200>,
			<100 0>;
		qcom,lut-data = <7003 6012 5477 5106 5054 5040>,
			<6970 6062 5487 5107 5054 5040>,
			<6934 6092 5493 5107 5054 5041>,
			<6898 6107 5496 5107 5054 5041>,
			<6868 6113 5496 5108 5055 5042>,
			<6848 6114 5496 5108 5055 5042>,
			<6836 6095 5493 5108 5056 5043>,
			<6828 6067 5488 5109 5056 5043>,
			<6837 6072 5483 5110 5057 5044>,
			<6888 6128 5476 5111 5059 5046>,
			<6922 6165 5472 5114 5060 5047>,
			<6805 6110 5503 5120 5063 5048>,
			<6610 6020 5548 5129 5067 5049>,
			<6546 5987 5542 5130 5069 5051>,
			<6529 5956 5478 5126 5070 5054>,
			<6514 5935 5440 5124 5072 5058>,
			<6491 5925 5443 5138 5080 5063>,
			<6468 5909 5447 5160 5091 5067>,
			<6453 5886 5439 5161 5091 5069>,
			<6441 5846 5401 5142 5086 5068>,
			<6436 5813 5367 5122 5080 5066>,
			<6441 5793 5347 5108 5066 5055>,
			<6454 5779 5332 5098 5052 5043>,
			<6468 5778 5323 5094 5050 5041>,
			<6484 5791 5316 5093 5050 5041>,
			<6501 5808 5311 5092 5050 5041>,
			<6520 5827 5308 5093 5050 5041>,
			<6540 5850 5306 5095 5051 5042>,
			<6562 5874 5307 5097 5053 5043>,
			<6586 5900 5310 5098 5057 5045>,
			<6612 5929 5313 5100 5061 5047>,
			<6642 5961 5320 5103 5065 5052>,
			<6674 5996 5331 5105 5067 5056>,
			<6708 6033 5343 5105 5066 5054>,
			<6744 6070 5358 5104 5063 5047>,
			<6782 6111 5373 5102 5059 5044>,
			<6819 6156 5387 5098 5054 5043>,
			<6858 6204 5402 5093 5051 5042>,
			<6901 6253 5420 5092 5051 5043>,
			<6948 6303 5441 5094 5053 5044>,
			<6998 6357 5465 5097 5054 5046>,
			<7047 6419 5493 5102 5055 5046>,
			<7099 6489 5526 5105 5055 5046>,
			<7163 6569 5570 5103 5051 5040>,
			<7247 6664 5627 5107 5055 5043>,
			<7271 6664 5640 5115 5065 5055>,
			<7313 6719 5680 5121 5074 5066>,
			<7379 6776 5726 5130 5088 5080>,
			<7448 6846 5769 5145 5091 5077>,
			<7509 6906 5799 5146 5073 5057>,
			<7555 6945 5808 5129 5071 5055>,
			<7635 7003 5852 5141 5077 5060>,
			<7764 7123 5956 5151 5087 5070>,
			<7927 7282 6078 5187 5129 5114>,
			<7927 7282 6078 5187 5129 5114>,
			<7927 7282 6078 5187 5129 5114>;
	};
};
